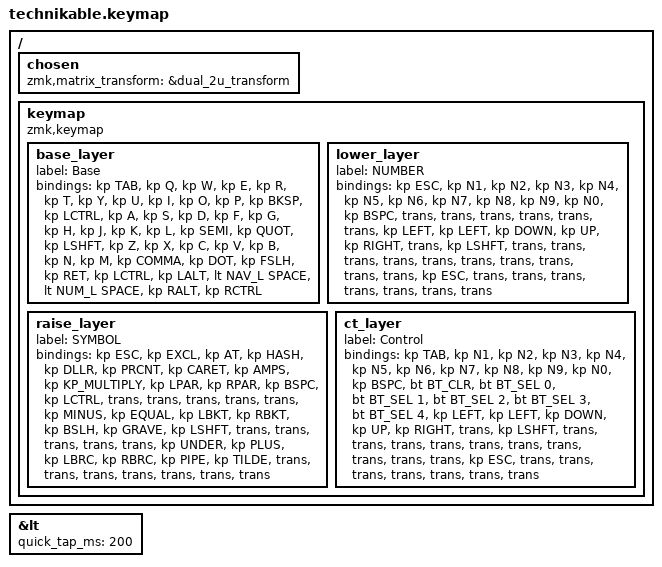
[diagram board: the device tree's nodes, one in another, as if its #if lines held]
/*
 * Copyright (c) 2022 Pete Johanson
 *
 * SPDX-License-Identifier: MIT
 */

#include <behaviors.dtsi>
#include <dt-bindings/zmk/keys.h>
#include <dt-bindings/zmk/bt.h>
#include <dt-bindings/zmk/outputs.h>

#define QWERTY_BASE 1

//#define TBLE_ORTHO   true
#define TBLE_MIT     true
// #define TBLE_DUAL_2U true

#define BAS_L 0
#define NUM_L 1
#define SYM_L 2
#define CT_L 3

// Using layer taps on thumbs, having quick tap as well helps w/ repeating space/backspace
&lt { quick_tap_ms = <200>; };

#define BT(n) BT_SEL n

/ {
    chosen {
       zmk,matrix_transform =
#ifdef TBLE_DUAL_2U
                       &dual_2u_transform;
#elif defined(TBLE_MIT)
                       &mit_transform;
#else
                       &ortho_transform;
#endif
    };

    keymap {
        compatible = "zmk,keymap";

        base_layer {
            label = "Base";
            bindings = <
#ifdef QWERTY_BASE
 &kp TAB    &kp Q      &kp W      &kp E       &kp R          &kp T          &kp Y            &kp U          &kp I       &kp O      &kp P         &kp BKSP
 &kp LCTRL  &kp A      &kp S      &kp D       &kp F          &kp G          &kp H            &kp J          &kp K       &kp L      &kp SEMI      &kp QUOT
 &kp LSHFT  &kp Z      &kp X      &kp C       &kp V          &kp B          &kp N            &kp M          &kp COMMA   &kp DOT    &kp FSLH      &kp RET
#else
 &kp ESC    &kp Q      &kp W      &kp F       &kp P          &kp B          &kp J            &kp L          &kp U       &kp Y      &kp QUOT     &kp BKSP
 &kp TAB    &kp A      &kp R      &kp S       &kp T          &kp G          &kp M            &kp N          &kp E       &kp I      &kp O        &kp QUOT
 &kp LSHFT  &kp Z      &kp X      &kp C       &kp D          &kp V          &kp K            &kp H          &kp COMMA   &kp DOT    &kp FSLH     &kp RET
#endif
#ifdef TBLE_DUAL_2U
                       &kp LCTRL  &kp LALT      &lt NAV_L SPACE                &lt NUM_L SPACE              &kp RALT    &kp RCTRL
#elif defined(TBLE_MIT)
                       &mo CT_L  &kp LGUI    &mo NUM_L          &kp SPACE                   &mo SYM_L      &kp RALT    &kp RCTRL
#else
                       &kp LCTRL  &kp LALT    &mo NAV_L      &kp SPACE      &kp SPACE        &mo NUM_L      &kp RALT    &kp RCTRL
#endif
            >;
        };
        lower_layer {
                        label = "NUMBER";
// -----------------------------------------------------------------------------------------
// |  TAB |  1  |  2  |  3  |  4  |  5  |   |  6  |  7  |  8  |  9  |  0  | BKSP |
// | BTCLR| BT1 | BT2 | BT3 | BT4 | BT5 |   | LFT | DWN |  UP | RGT |     |      |
// | SHFT |     |     |     |     |     |   |     |     |     |     |     |      |
//                    | GUI |     | SPC |   | ENT |     | ALT |
                        bindings = <
   &kp ESC    &kp N1       &kp N2       &kp N3       &kp N4       &kp N5         &kp N6   &kp N7   &kp N8       &kp N9  &kp N0          &kp BSPC
   &trans &trans       &trans       &trans       &trans       &trans   &kp LEFT &kp LEFT &kp DOWN     &kp UP  &kp RIGHT       &trans
   &kp LSHFT  &trans       &trans       &trans       &trans       &trans         &trans   &trans   &trans       &trans  &trans          &kp ESC
                          	        &trans     &trans       &trans       &trans   &trans   &trans &trans  
                        >;
                };

                raise_layer {
                        label = "SYMBOL";
// -----------------------------------------------------------------------------------------
// |  ESC |  !  |  @  |  #  |  $  |  %  |   |  ^  |  &  |  *  |  (  |  )  | BKSP |
// | CTRL |     |     |     |     |     |   |  -  |  =  |  [  |  ]  |  \  |  `   |
// | SHFT |     |     |     |     |     |   |  _  |  +  |  {  |  }  | "|" |  ~   |
//                    | GUI |     | SPC |   | ENT |     | ALT |
                        bindings = <
   &kp  ESC  &kp EXCL &kp AT &kp HASH &kp DLLR &kp PRCNT   &kp CARET &kp AMPS  &kp KP_MULTIPLY &kp LPAR &kp RPAR &kp BSPC
   &kp LCTRL &trans   &trans &trans   &trans   &trans      &kp MINUS &kp EQUAL &kp LBKT        &kp RBKT &kp BSLH &kp GRAVE
   &kp LSHFT &trans   &trans &trans   &trans   &trans      &kp UNDER &kp PLUS  &kp LBRC        &kp RBRC &kp PIPE &kp TILDE
                    	     &trans     &trans       &trans       &trans   &trans   &trans &trans
                        >;
                };
		
		ct_layer {
                        label = "Control";
// -----------------------------------------------------------------------------------------
// |  TAB |  1  |  2  |  3  |  4  |  5  |   |  6  |  7  |  8  |  9  |  0  | BKSP |
// | BTCLR| BT1 | BT2 | BT3 | BT4 | BT5 |   | LFT | DWN |  UP | RGT |     |      |
// | SHFT |     |     |     |     |     |   |     |     |     |     |     |      |
//                    | GUI |     | SPC |   | ENT |     | ALT |
                        bindings = <
   &kp TAB    &kp N1       &kp N2       &kp N3       &kp N4       &kp N5         &kp N6   &kp N7   &kp N8       &kp N9  &kp N0          &kp BSPC
   &bt BT_CLR &bt BT_SEL 0 &bt BT_SEL 1 &bt BT_SEL 2 &bt BT_SEL 3 &bt BT_SEL 4   &kp LEFT &kp LEFT &kp DOWN     &kp UP  &kp RIGHT       &trans
   &kp LSHFT  &trans       &trans       &trans       &trans       &trans         &trans   &trans   &trans       &trans  &trans          &kp ESC
                          	        &trans     &trans       &trans       &trans   &trans   &trans &trans  
                        >;
                };

    };
};

